# soc_system_hps_0_hps register map
Vendor: default_vendor.com; File version: 0.0
Registers are 32-bit, read-write, reset 0x0 unless marked. A register's access mark holds for its fields unless they carry their own. Offsets are from the block's base; [hi:lo] are bit positions.

## stm — Address space allocated to the STM. For detailed information about the use of this address space, [url=http://infocenter.arm.com/help/index.jsp?topic=/com.arm.doc.ddi0444b/index.html]click here[/url] to access the ARM documentation for the CoreSight STM-101.
Base 0xFC000000
Same registers: dap 0xFF000000, dmanonsecure 0xFFE00000, dmasecure 0xFFE01000, mpuscu 0xFFFEC000, mpul2 0xFFFEF000
0x00 reg reset not defined — Placeholder
  [31:0] fld

## fpgamgrdata — Registers in the FPGA Manager module accessible via its AXI slave
Base 0xFFB90000
0x00 data reset not defined — Used to send configuration image to FPGA. The DATA register accepts 4 bytes of the configuration image on each write. The configuration image byte-stream is converted into a 4-byte word with little-endian ordering. If the configuration image is not an integer multiple of 4 bytes, software should pad the configuration image with extra zero bytes to make it an integer multiple of 4 bytes. The FPGA Manager converts the DATA to 16 bits wide when writing CB.DATA for partial reconfiguration. The FPGA Manager waits to transmit the data to the CB until the FPGA is able to receive it. For a full configuration, the FPGA Manager waits until the FPGA exits the Reset Phase and enters the Configuration Phase. For a partial reconfiguration, the FPGA Manager waits until the CB.PR_READY signal indicates that the FPGA is ready.
  [31:0] value — Accepts configuration image to be sent to CB when the HPS configures the FPGA. Software normally just writes this register. If software reads this register, it returns the value 0 and replies with an AXI SLVERR error.

## sptimer0 — Registers in the timer module. The timer IP core supports multiple timers but it is configured for just one timer. The term Timer1 refers to this one timer in the IP core and not the module instance.
Base 0xFFC08000
Same registers: sptimer1 0xFFC09000, osc1timer0 0xFFD00000, osc1timer1 0xFFD01000
0x00 timer1loadcount — Used to load counter value into Timer1
  [31:0] timer1loadcount — Value to be loaded into Timer1. This is the value from which counting commences. Any value written to this register is loaded into the associated timer.
0x04 timer1currentval ro — Provides current value of Timer1
  [31:0] timer1currentval — Current value of Timer1.
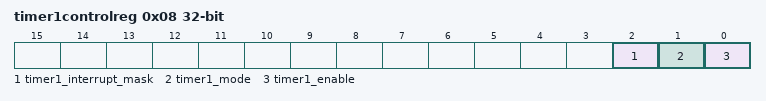
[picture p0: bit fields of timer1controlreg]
0x08 timer1controlreg — This register controls enabling, operating mode (free-running or user-defined-count), and interrupt mask of Timer1. You can program this register to enable or disable Timer1 and to control its mode of operation.
  [2] timer1_interrupt_mask
    0=notmasked; 1=masked
  [1] timer1_mode — Sets operating mode. NOTE: You must set the timer1loadcount register to all ones before enabling the timer in free-running mode.
    0=freerun; 1=usedef
  [0] timer1_enable — Timer1 enable/disable bit.
    0=disabled; 1=enabled
0x0C timer1eoi ro — Clears Timer1 interrupt when read.
  [0] timer1eoi — Reading from this register clears the interrupt from Timer1 and returns 0.
0x10 timer1intstat ro — Provides the interrupt status of Timer1 after masking.
  [0] timer1intstat — Provides the interrupt status for Timer1. The status reported is after the interrupt mask has been applied. Reading from this register does not clear any active interrupts.
    0=inactive; 1=active
0xA0 timersintstat ro — Provides the interrupt status for all timers after masking. Because there is only Timer1 in this module instance, this status is the same as timer1intstat.
  [0] timersintstat — Provides the interrupt status for Timer1. Because there is only Timer1 in this module instance, this status is the same as timer1intstat. The status reported is after the interrupt mask has been applied. Reading from this register does not clear any active interrupts.
    0=inactive; 1=active
0xA4 timerseoi ro — Clears Timer1 interrupt when read. Because there is only Timer1 in this module instance, reading this register has the same effect as reading timer1eoi.
  [0] timerseoi — Reading from this register clears the interrupt all timers and returns 0. Because there is only Timer1 in this module instance, reading this register has the same effect as reading timer1eoi.
0xA8 timersrawintstat ro — Provides the interrupt status for all timers before masking. Note that there is only Timer1 in this module instance.
  [0] timersrawintstat — Provides the interrupt status for Timer1. Because there is only Timer1 in this module instance, this status is the same as timer1intstat. The status reported is before the interrupt mask has been applied. Reading from this register does not clear any active interrupts.
    0=inactive; 1=active
0xAC timerscompversion ro reset 0x3230352A
  [31:0] timerscompversion — Current revision number of the timers component.

## altera_avalon_jtag_uart_jtag_uart_avalon_jtag_slave
Base 0xC0000000
Same registers: altera_avalon_jtag_uart_jtag_uart_avalon_jtag_slave 0xFF220000, altera_avalon_jtag_uart_jtag_uart_avalon_jtag_slave 0xFF220000
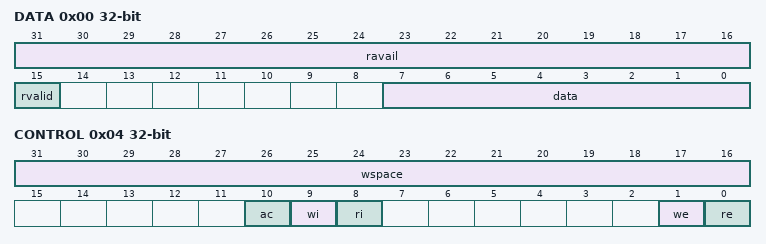
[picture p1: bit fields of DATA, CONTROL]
0x00 DATA — Embedded software accesses the read and write FIFOs via the data register. A read from the data register returns the first character from the FIFO (if one is available) in the DATA field. Reading also returns information about the number of characters remaining in the FIFO in the RAVAIL field. A write to the data register stores the value of the DATA field in the write FIFO. If the write FIFO is full, the character is lost.
  [31:16] ravail ro — The number of characters remaining in the read FIFO (after the current read).
  [15] rvalid ro — Indicates whether the DATA field is valid. If RVALID=1, the DATA field is valid, otherwise DATA is undefined.
  [7:0] data — The value to transfer to/from the JTAG core. When writing, the DATA field holds a character to be written to the write FIFO. When reading, the DATA field holds a character read from the read FIFO.
0x04 CONTROL — Embedded software controls the JTAG UART core's interrupt generation and reads status information via the control register. A read from the control register returns the status of the read and write FIFOs. Writes to the register can be used to enable/disable interrupts, or clear the AC bit.
  [31:16] wspace ro — The number of spaces available in the write FIFO
  [10] ac — Indicates that there has been JTAG activity since the bit was cleared. Writing 1 to AC clears it to 0.
  [9] wi ro — Indicates that the write interrupt is pending.
  [8] ri ro — Indicates that the read interrupt is pending.
  [1] we — Interrupt-enable bit for write interrupts
  [0] re — Interrupt-enable bit for read interrupts.

## altera_avalon_sysid_sysid_qsys_control_slave
Base 0xFF200190
0x00 ID ro reset 0xACD51302 — A unique 32-bit value that is based on the contents of the QSys system. The id is similar to a check-sum value; QSys systems with different components, different configuration options, or both, produce different id values.
0x04 TIMESTAMP ro reset 0x6AE24AC7 — A unique 32-bit value that is based on the system generation time. The value is equivalent to the number of seconds after Jan. 1, 1970.
